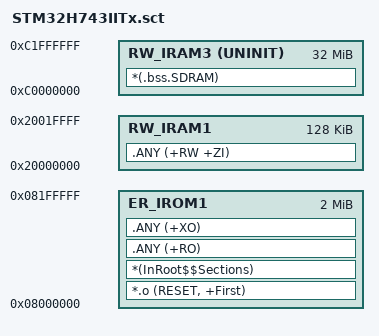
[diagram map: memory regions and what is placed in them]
; *************************************************************
; *** Scatter-Loading Description File generated by uVision ***
; *************************************************************

LR_IROM1 0x08000000 0x00200000  {    ; load region size_region
  ER_IROM1 0x08000000 0x00200000  {  ; load address = execution address
   *.o (RESET, +First)
   *(InRoot$$Sections)
   .ANY (+RO)
   .ANY (+XO)
  }
  RW_IRAM1 0x20000000 0x00020000  {  ; RW data
   .ANY (+RW +ZI)
  }
;  RW_IRAM2 0x24000000 0x00080000  {  ; RW data AXI SRAM 512KB
;   *(.AXI_RAM)
;  }
  RW_IRAM3  0xC0000000 UNINIT 0x02000000  { ; SDRAM 32MB SDRAM在main函数中初始化,因此需要设置UNINIT防止main之前访问
   *(.bss.SDRAM)                            ; 段名.bss开头表示在ZI段创建变量
  }
}

